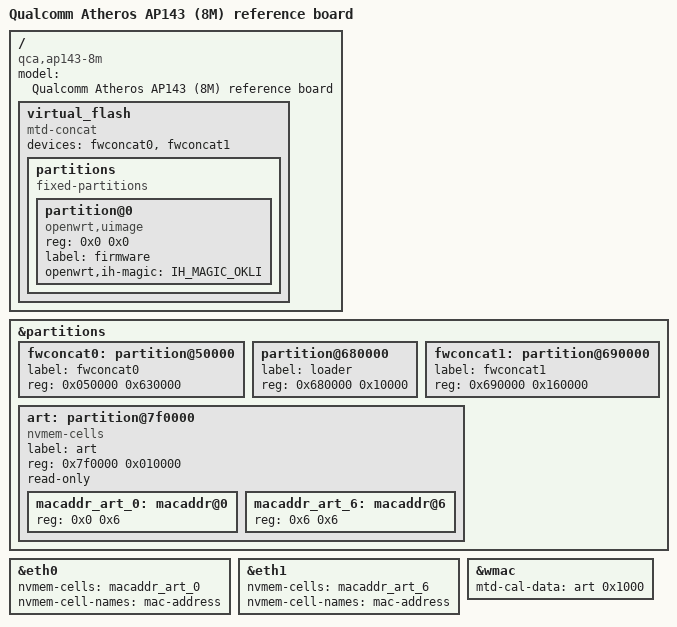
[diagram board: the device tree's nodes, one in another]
// SPDX-License-Identifier: GPL-2.0-or-later OR MIT

#include "qca9533_qca_ap143.dtsi"

/ {
	model = "Qualcomm Atheros AP143 (8M) reference board";
	compatible = "qca,ap143-8m", "qca,qca9533";

	virtual_flash {
		compatible = "mtd-concat";
		devices = <&fwconcat0 &fwconcat1>;

		partitions {
			compatible = "fixed-partitions";
			#address-cells = <1>;
			#size-cells = <1>;

			partition@0 {
				reg = <0x0 0x0>;
				label = "firmware";
				compatible = "openwrt,uimage", "denx,uimage";
				openwrt,ih-magic = <IH_MAGIC_OKLI>;
			};
		};
	};
};

&partitions {
	fwconcat0: partition@50000 {
		label = "fwconcat0";
		reg = <0x050000 0x630000>;
	};

	partition@680000 {
		label = "loader";
		reg = <0x680000 0x10000>;
	};

	fwconcat1: partition@690000 {
		label = "fwconcat1";
		reg = <0x690000 0x160000>;
	};

	art: partition@7f0000 {
		label = "art";
		reg = <0x7f0000 0x010000>;
		read-only;
	};
};

&eth0 {
	nvmem-cells = <&macaddr_art_0>;
	nvmem-cell-names = "mac-address";
};

&eth1 {
	nvmem-cells = <&macaddr_art_6>;
	nvmem-cell-names = "mac-address";
};

&wmac {
	mtd-cal-data = <&art 0x1000>;
};

&art {
	compatible = "nvmem-cells";
	#address-cells = <1>;
	#size-cells = <1>;

	macaddr_art_0: macaddr@0 {
		reg = <0x0 0x6>;
	};

	macaddr_art_6: macaddr@6 {
		reg = <0x6 0x6>;
	};
};
